# CY8C5888LTI_LP097 register map
File version: 0.1
CY8C58LP
Registers are 8-bit, read-write, no defined reset value unless marked. A register's access mark holds for its fields unless they carry their own. Offsets are from the block's base; lines under a group give offsets from that group; [hi:lo] are bit positions; {n}, {i} and the like mark numbered series; 'fields as' and 'values as' point back to an identical list; <NAME> marks a mode.

## Memory map
0x00000000 UARTQS — UART
0x00000000 UARTA — UART

## UARTQS — UART
Base 0x00000000
0x40006447 TX_UARTQS_TX_DATA — TX Data Register
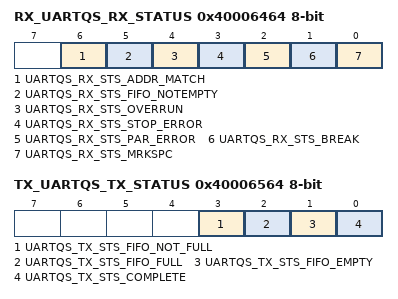
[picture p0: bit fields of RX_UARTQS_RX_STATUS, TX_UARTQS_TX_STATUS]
0x40006464 RX_UARTQS_RX_STATUS — RX status register
  [6] UARTQS_RX_STS_ADDR_MATCH ro, [5] UARTQS_RX_STS_FIFO_NOTEMPTY ro, [4] UARTQS_RX_STS_OVERRUN ro, [3] UARTQS_RX_STS_STOP_ERROR ro, [2] UARTQS_RX_STS_PAR_ERROR ro, [1] UARTQS_RX_STS_BREAK ro, [0] UARTQS_RX_STS_MRKSPC ro
0x40006527 RX_UARTQS_RX_ADDRESS1 — RX Address1 Register
0x40006537 RX_UARTQS_RX_ADDRESS2 — RX Address2 Register
0x40006547 RX_UARTQS_RX_DATA — RX Data Register
0x40006564 TX_UARTQS_TX_STATUS — TX status register
  [3] UARTQS_TX_STS_FIFO_NOT_FULL ro, [2] UARTQS_TX_STS_FIFO_FULL ro, [1] UARTQS_TX_STS_FIFO_EMPTY ro, [0] UARTQS_TX_STS_COMPLETE ro

## UARTA — UART
Base 0x00000000
0x40006424 RX_UARTA_RX_ADDRESS1 — RX Address1 Register
0x40006434 RX_UARTA_RX_ADDRESS2 — RX Address2 Register
0x40006444 RX_UARTA_RX_DATA — RX Data Register
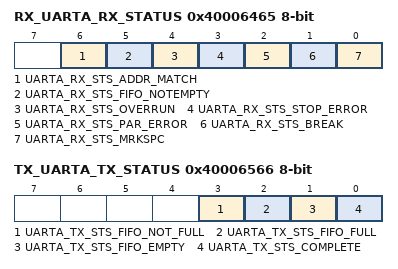
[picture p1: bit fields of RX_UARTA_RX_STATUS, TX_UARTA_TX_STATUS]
0x40006465 RX_UARTA_RX_STATUS — RX status register
  [6] UARTA_RX_STS_ADDR_MATCH ro, [5] UARTA_RX_STS_FIFO_NOTEMPTY ro, [4] UARTA_RX_STS_OVERRUN ro, [3] UARTA_RX_STS_STOP_ERROR ro, [2] UARTA_RX_STS_PAR_ERROR ro, [1] UARTA_RX_STS_BREAK ro, [0] UARTA_RX_STS_MRKSPC ro
0x40006545 TX_UARTA_TX_DATA — TX Data Register
0x40006566 TX_UARTA_TX_STATUS — TX status register
  [3] UARTA_TX_STS_FIFO_NOT_FULL ro, [2] UARTA_TX_STS_FIFO_FULL ro, [1] UARTA_TX_STS_FIFO_EMPTY ro, [0] UARTA_TX_STS_COMPLETE ro
